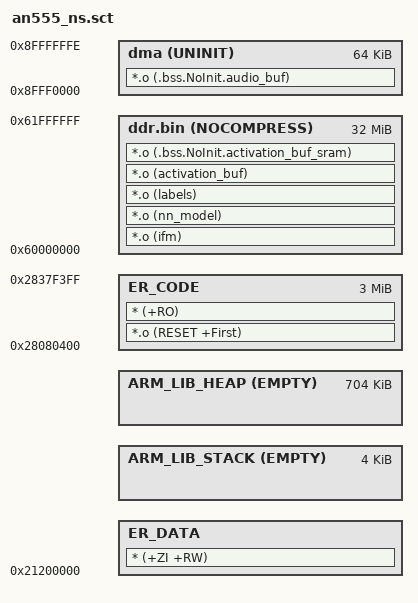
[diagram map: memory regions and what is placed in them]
/*
 * Copyright (c) 2021-2023 Arm Limited. All rights reserved.
 *
 * Licensed under the Apache License, Version 2.0 (the "License");
 * you may not use this file except in compliance with the License.
 * You may obtain a copy of the License at
 *
 *     http://www.apache.org/licenses/LICENSE-2.0
 *
 * Unless required by applicable law or agreed to in writing, software
 * distributed under the License is distributed on an "AS IS" BASIS,
 * WITHOUT WARRANTIES OR CONDITIONS OF ANY KIND, either express or implied.
 * See the License for the specific language governing permissions and
 * limitations under the License.
 */

LR_CODE (0x28000000 + ((((0) + (0x80000)) + 0x400))) {
    ER_CODE (0x28000000 + ((((0) + (0x80000)) + 0x400))) (((0x300000) - 0x400 - 0xC00)) {
        *.o (RESET +First)
        * (+RO)
    }

    ER_DATA (0x21000000 + ((0x00200000))) {
        * (+ZI +RW)
    }


    ARM_LIB_STACK +0 ALIGN 32 EMPTY (0x0001000) {
    }

    ARM_LIB_HEAP +0 ALIGN 8 EMPTY (0x00b0000) {
    }

    ;-----------------------------------------------------
    ; SSE-300's internal SRAM of 4MiB - reserved for
    ; activation buffers.
    ; This region should have 3 cycle read latency from
    ; both Cortex-M55 and Ethos-U55
    ;-----------------------------------------------------
    ddr.bin       0x60000000  NOCOMPRESS ALIGN 16 0x02000000
    {
        ; nn model's baked in input matrices
        *.o (ifm)

        ; nn model
        *.o (nn_model)

        ; labels
        *.o (labels)

        ; if the activation buffer (tensor arena) doesn't
        ; fit in the SRAM region, we accommodate it here
        *.o (activation_buf)

        ; activation buffers a.k.a tensor arena when memory mode dedicated sram
        *.o (.bss.NoInit.activation_buf_sram)
    }

    dma 0x8FFF0000 UNINIT ALIGN 16 0xFFFF
    {
        ; Buffer for transferring VSI audio data from S to NS.
        *.o (.bss.NoInit.audio_buf)
    }
}
